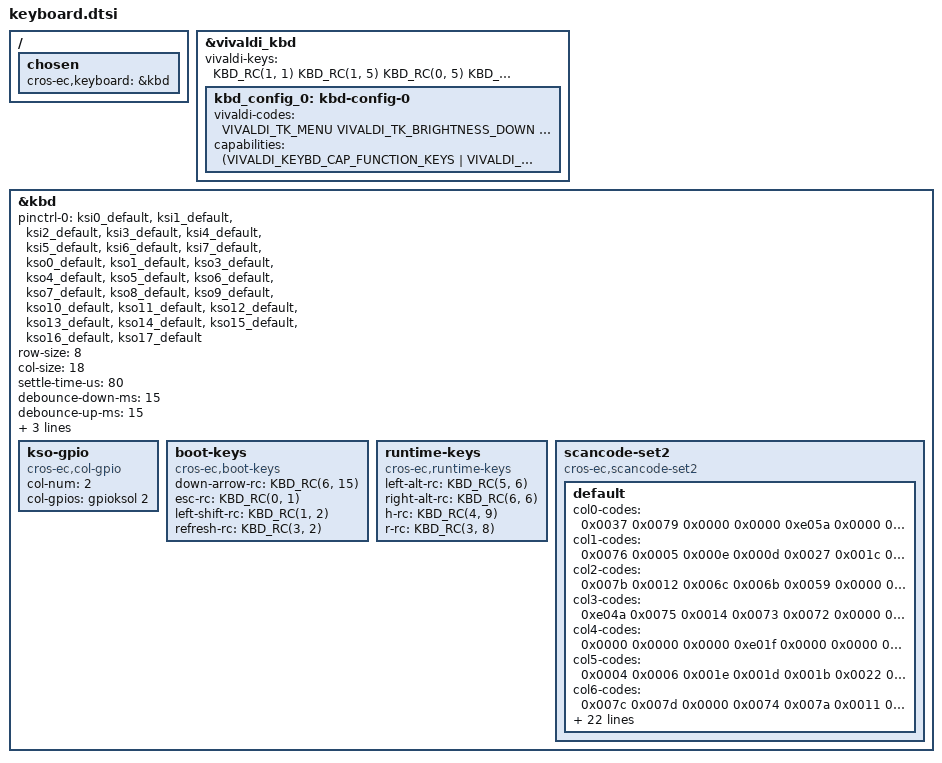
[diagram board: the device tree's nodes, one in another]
/* Copyright 2025 The ChromiumOS Authors
 * Use of this source code is governed by a BSD-style license that can be
 * found in the LICENSE file.
 */

/ {
	chosen {
		cros-ec,keyboard = &kbd;
	};
};

&vivaldi_kbd {
	vivaldi-keys = <
		KBD_RC(1, 1)    /* T1 */
		KBD_RC(1, 5)    /* T2 */
		KBD_RC(0, 5)    /* T3 */
		KBD_RC(1, 7)    /* T4 */
		KBD_RC(0, 7)    /* T5 */
		KBD_RC(0, 8)    /* T6 */
		KBD_RC(0, 9)    /* T7 */
		KBD_RC(1, 10)   /* T8 */
		KBD_RC(0, 10)   /* T9 */
		KBD_RC(0, 12)   /* T10 */
		KBD_RC(0, 13)   /* T11 */
		KBD_RC(1, 13)   /* T12 */
		KBD_RC(1, 15)   /* T13 */
		KBD_RC(7, 11)   /* T14 */
		KBD_RC(0, 14)   /* T15 */
 	>;

	kbd_config_0: kbd-config-0{
		vivaldi-codes = <
			VIVALDI_TK_MENU                 /* T1 */
			VIVALDI_TK_BRIGHTNESS_DOWN      /* T2 */
			VIVALDI_TK_BRIGHTNESS_UP        /* T3 */
			VIVALDI_TK_FULLSCREEN           /* T4 */
			VIVALDI_TK_OVERVIEW             /* T5 */
			VIVALDI_TK_VOL_MUTE             /* T6 */
			VIVALDI_TK_VOL_DOWN             /* T7 */
			VIVALDI_TK_VOL_UP               /* T8 */
			VIVALDI_TK_FORWARD              /* T9 */
			VIVALDI_TK_SNAPSHOT             /* T10 */
			VIVALDI_TK_MICMUTE              /* T11 */
			VIVALDI_TK_PREV_TRACK           /* T12 */
			VIVALDI_TK_PLAY_PAUSE           /* T13 */
			VIVALDI_TK_NEXT_TRACK           /* T14 */
			VIVALDI_TK_BACK                 /* T15 */
		>;
		capabilities = < (VIVALDI_KEYBD_CAP_FUNCTION_KEYS |
				VIVALDI_KEYBD_CAP_SCRNLOCK_KEY |
				VIVALDI_KEYBD_CAP_NUMERIC_KEYPAD |
				VIVALDI_KEYBD_CAP_ASSISTANT_KEY) >;
	};
};

&kbd {
	status = "okay";
	/* No KSO2 (it's inverted and implemented by GPIO) */
	pinctrl-0 = <
		&ksi0_default
		&ksi1_default
		&ksi2_default
		&ksi3_default
		&ksi4_default
		&ksi5_default
		&ksi6_default
		&ksi7_default
		&kso0_default
		&kso1_default
		&kso3_default
		&kso4_default
		&kso5_default
		&kso6_default
		&kso7_default
		&kso8_default
		&kso9_default
		&kso10_default
		&kso11_default
		&kso12_default
		&kso13_default
		&kso14_default
		&kso15_default
		&kso16_default
		&kso17_default
	>;

	pinctrl-names = "default";
	row-size = <8>;
	col-size = <18>;
	settle-time-us = <80>;
	debounce-down-ms = <15>;
	debounce-up-ms = <15>;
	actual-key-mask = <0x9b 0xff 0x5f 0x9f 0x08 0xff 0x7b 0xff
			   0xff 0xff 0xff 0xff 0xff 0xff 0xff 0xff 0xff 0xff>;
	kso-ignore-mask = <04>;

	kso-gpio {
		compatible = "cros-ec,col-gpio";
		col-num = <2>;
		col-gpios = <&gpioksol 2 GPIO_ACTIVE_HIGH>;
	};

	boot-keys {
		compatible = "cros-ec,boot-keys";
		down-arrow-rc = <KBD_RC(6, 15)>;
		esc-rc = <KBD_RC(0, 1)>;
		left-shift-rc = <KBD_RC(1, 2)>;
		refresh-rc = <KBD_RC(3, 2)>;
	};

	runtime-keys {
		compatible = "cros-ec,runtime-keys";
		left-alt-rc = <KBD_RC(5, 6)>;
		right-alt-rc = <KBD_RC(6, 6)>;
		h-rc = <KBD_RC(4, 9)>;
		r-rc = <KBD_RC(3, 8)>;
	};

	scancode-set2 {
		compatible = "cros-ec,scancode-set2";

		default {
			col0-codes  = <0x0037 0x0079 0x0000 0x0000 0xe05a 0x0000 0x0000 0x0070>;
			col1-codes  = <0x0076 0x0005 0x000e 0x000d 0x0027 0x001c 0x006a 0x0016>;
			col2-codes  = <0x007b 0x0012 0x006c 0x006b 0x0059 0x0000 0x0069 0x0000>;
			col3-codes  = <0xe04a 0x0075 0x0014 0x0073 0x0072 0x0000 0x0000 0x0071>;
			col4-codes  = <0x0000 0x0000 0x0000 0xe01f 0x0000 0x0000 0x0000 0x0000>;
			col5-codes  = <0x0004 0x0006 0x001e 0x001d 0x001b 0x0022 0x001a 0x0015>;
			col6-codes  = <0x007c 0x007d 0x0000 0x0074 0x007a 0x0011 0xe011 0x0000>;
			col7-codes  = <0x0003 0x000c 0x0025 0x0024 0x0023 0x0021 0x0000 0x0026>;
			col8-codes  = <0x000b 0x0036 0x002e 0x002d 0x0034 0x002b 0x002a 0x002c>;
			col9-codes  = <0x0083 0x003e 0x003d 0x0035 0x0033 0x0031 0x0032 0x003c>;
			col10-codes = <0x0001 0x000a 0x0043 0x0042 0x003a 0x0041 0x0029 0x003b>;
			col11-codes = <0x0077 0x0000 0x0051 0x005d 0x0000 0x0000 0xe014 0xe07c>;
			col12-codes = <0x0009 0x0046 0x0044 0x004b 0x0000 0x0049 0x0052 0x004d>;
			col13-codes = <0xe01f 0x0000 0x0045 0x0054 0x0000 0x004a 0xe071 0x004e>;
			col14-codes = <0xe06c 0x0000 0x0055 0x0061 0xe075 0x0000 0xe06b 0x005b>;
			col15-codes = <0x0000 0x007e 0x0066 0x005a 0x005d 0x004c 0xe072 0xe074>;
			col16-codes = <0x0000 0x0000 0x0000 0x0000 0x0000 0x0000 0x0000 0x0000>;
			col17-codes = <0x0000 0x0000 0x0000 0x0000 0x0000 0x0000 0x0000 0x0000>;
		};
	};
};
